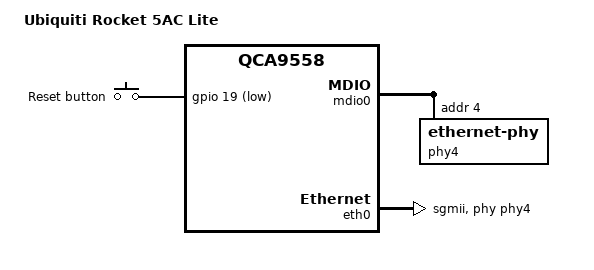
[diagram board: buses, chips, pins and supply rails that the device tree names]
// SPDX-License-Identifier: GPL-2.0-only

#include "qca955x_ubnt_xc.dtsi"

/ {
	compatible = "ubnt,rocket-5ac-lite", "ubnt,xc", "qca,qca9558";
	model = "Ubiquiti Rocket 5AC Lite";

	keys {
		compatible = "gpio-keys";

		reset {
			label = "Reset button";
			linux,code = <KEY_RESTART>;
			gpios = <&gpio 19 GPIO_ACTIVE_LOW>;
			debounce-interval = <60>;
		};
	};
};

&mdio0 {
	status = "okay";

	phy-mask = <4>;
	phy4: ethernet-phy@4 {
		phy-mode = "sgmii";
		reg = <4>;
		at803x-override-sgmii-link-check;
	};
};

&eth0 {
	status = "okay";

	mtd-mac-address = <&art 0x0>;
	phy-mode = "sgmii";
	phy-handle = <&phy4>;
};
